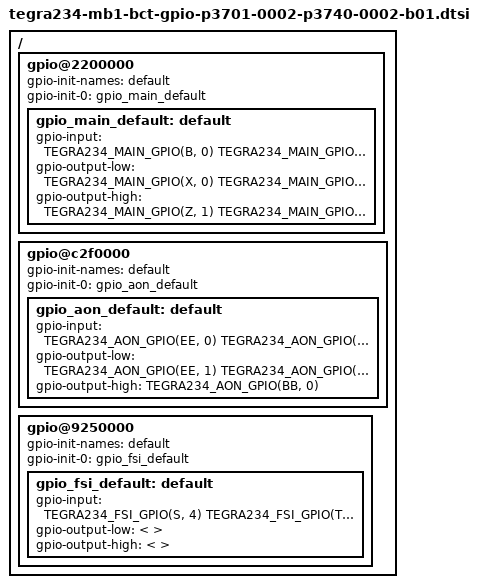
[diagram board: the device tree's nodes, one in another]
/*
 * SPDX-FileCopyrightText: Copyright (c) 2023, NVIDIA CORPORATION & AFFILIATES. All rights reserved.
 * SPDX-License-Identifier: BSD-3-Clause
 *
 * Redistribution and use in source and binary forms, with or without
 * modification, are permitted provided that the following conditions are met:
 *
 * 1. Redistributions of source code must retain the above copyright notice, this
 * list of conditions and the following disclaimer.
 *
 * 2. Redistributions in binary form must reproduce the above copyright notice,
 * this list of conditions and the following disclaimer in the documentation
 * and/or other materials provided with the distribution.
 *
 * 3. Neither the name of the copyright holder nor the names of its
 * contributors may be used to endorse or promote products derived from
 * this software without specific prior written permission.
 *
 * THIS SOFTWARE IS PROVIDED BY THE COPYRIGHT HOLDERS AND CONTRIBUTORS "AS IS"
 * AND ANY EXPRESS OR IMPLIED WARRANTIES, INCLUDING, BUT NOT LIMITED TO, THE
 * IMPLIED WARRANTIES OF MERCHANTABILITY AND FITNESS FOR A PARTICULAR PURPOSE ARE
 * DISCLAIMED. IN NO EVENT SHALL THE COPYRIGHT HOLDER OR CONTRIBUTORS BE LIABLE
 * FOR ANY DIRECT, INDIRECT, INCIDENTAL, SPECIAL, EXEMPLARY, OR CONSEQUENTIAL
 * DAMAGES (INCLUDING, BUT NOT LIMITED TO, PROCUREMENT OF SUBSTITUTE GOODS OR
 * SERVICES; LOSS OF USE, DATA, OR PROFITS; OR BUSINESS INTERRUPTION) HOWEVER
 * CAUSED AND ON ANY THEORY OF LIABILITY, WHETHER IN CONTRACT, STRICT LIABILITY,
 * OR TORT (INCLUDING NEGLIGENCE OR OTHERWISE) ARISING IN ANY WAY OUT OF THE USE
 * OF THIS SOFTWARE, EVEN IF ADVISED OF THE POSSIBILITY OF SUCH DAMAGE.
 */
/*This dtsi file was generated by ARM_PC_P3740_B01_T234.xlsm Revision: 14 */

#include "tegra234-gpio.h"

/ {
	gpio@2200000 {
		gpio-init-names = "default";
		gpio-init-0 = <&gpio_main_default>;

		gpio_main_default: default {
			gpio-input = <
				TEGRA234_MAIN_GPIO(B, 0)
				TEGRA234_MAIN_GPIO(Y, 4)
				TEGRA234_MAIN_GPIO(Q, 6)
				TEGRA234_MAIN_GPIO(R, 1)
				TEGRA234_MAIN_GPIO(N, 3)
				TEGRA234_MAIN_GPIO(N, 4)
				TEGRA234_MAIN_GPIO(M, 6)
				TEGRA234_MAIN_GPIO(N, 2)
				TEGRA234_MAIN_GPIO(G, 0)
				TEGRA234_MAIN_GPIO(G, 1)
				TEGRA234_MAIN_GPIO(G, 2)
				TEGRA234_MAIN_GPIO(G, 4)
				TEGRA234_MAIN_GPIO(G, 5)
				TEGRA234_MAIN_GPIO(H, 1)
				TEGRA234_MAIN_GPIO(H, 4)
				TEGRA234_MAIN_GPIO(H, 5)
				TEGRA234_MAIN_GPIO(E, 0)
				TEGRA234_MAIN_GPIO(E, 1)
				TEGRA234_MAIN_GPIO(E, 2)
				TEGRA234_MAIN_GPIO(E, 3)
				TEGRA234_MAIN_GPIO(E, 4)
				TEGRA234_MAIN_GPIO(E, 5)
				TEGRA234_MAIN_GPIO(E, 7)
				TEGRA234_MAIN_GPIO(F, 1)
				TEGRA234_MAIN_GPIO(F, 2)
				TEGRA234_MAIN_GPIO(F, 3)
				TEGRA234_MAIN_GPIO(AC, 3)
				TEGRA234_MAIN_GPIO(AC, 4)
				TEGRA234_MAIN_GPIO(AC, 5)
				TEGRA234_MAIN_GPIO(K, 6)
				TEGRA234_MAIN_GPIO(L, 2)
				TEGRA234_MAIN_GPIO(L, 3)
				TEGRA234_MAIN_GPIO(AF, 0)
				TEGRA234_MAIN_GPIO(AF, 2)
				TEGRA234_MAIN_GPIO(AF, 3)
				>;
			gpio-output-low = <
				TEGRA234_MAIN_GPIO(X, 0)
				TEGRA234_MAIN_GPIO(X, 1)
				TEGRA234_MAIN_GPIO(Z, 7)
				TEGRA234_MAIN_GPIO(Q, 1)
				TEGRA234_MAIN_GPIO(Q, 4)
				TEGRA234_MAIN_GPIO(M, 3)
				TEGRA234_MAIN_GPIO(M, 4)
				TEGRA234_MAIN_GPIO(M, 5)
				TEGRA234_MAIN_GPIO(M, 7)
				TEGRA234_MAIN_GPIO(G, 3)
				TEGRA234_MAIN_GPIO(H, 0)
				TEGRA234_MAIN_GPIO(H, 3)
				TEGRA234_MAIN_GPIO(H, 6)
				TEGRA234_MAIN_GPIO(I, 5)
				TEGRA234_MAIN_GPIO(AC, 0)
				TEGRA234_MAIN_GPIO(AC, 1)
				TEGRA234_MAIN_GPIO(AC, 2)
				>;
			gpio-output-high = <
				TEGRA234_MAIN_GPIO(Z, 1)
				TEGRA234_MAIN_GPIO(P, 4)
				TEGRA234_MAIN_GPIO(Q, 7)
				TEGRA234_MAIN_GPIO(E, 6)
				TEGRA234_MAIN_GPIO(K, 4)
				TEGRA234_MAIN_GPIO(K, 5)
				TEGRA234_MAIN_GPIO(AG, 4)
				TEGRA234_MAIN_GPIO(AG, 5)
				>;
		};
	};
	gpio@c2f0000 {
		gpio-init-names = "default";
		gpio-init-0 = <&gpio_aon_default>;

		gpio_aon_default: default {
			gpio-input = <
				TEGRA234_AON_GPIO(EE, 0)
				TEGRA234_AON_GPIO(EE, 5)
				TEGRA234_AON_GPIO(EE, 6)
				TEGRA234_AON_GPIO(EE, 2)
				TEGRA234_AON_GPIO(EE, 7)
				TEGRA234_AON_GPIO(EE, 4)
				>;
			gpio-output-low = <
				TEGRA234_AON_GPIO(EE, 1)
				TEGRA234_AON_GPIO(AA, 4)
				TEGRA234_AON_GPIO(AA, 7)
				TEGRA234_AON_GPIO(BB, 2)
				>;
			gpio-output-high = <
				TEGRA234_AON_GPIO(BB, 0)
				>;
		};
	};
	gpio@9250000 {
		gpio-init-names = "default";
		gpio-init-0 = <&gpio_fsi_default>;

		gpio_fsi_default: default {
			gpio-input = <
				TEGRA234_FSI_GPIO(S, 4)
				TEGRA234_FSI_GPIO(T, 1)
				TEGRA234_FSI_GPIO(U, 7)
				TEGRA234_FSI_GPIO(V, 0)
				TEGRA234_FSI_GPIO(W, 0)
				TEGRA234_FSI_GPIO(W, 1)
				>;
			gpio-output-low = <
				>;
			gpio-output-high = <
				>;
		};
	};

};
